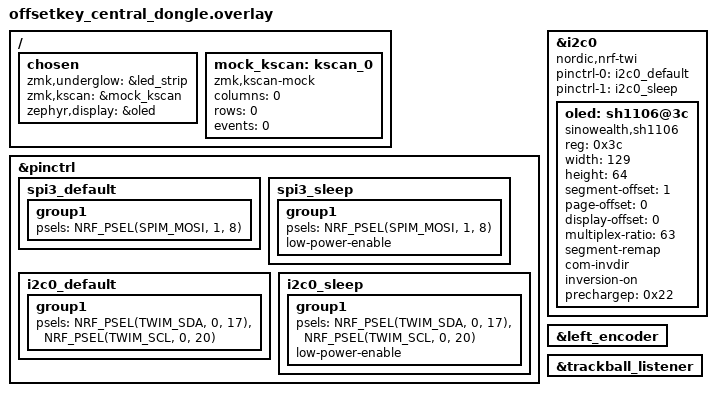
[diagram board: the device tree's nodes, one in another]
/*
 * Copyright (c) 2020 ZMK Contributors
 *
 * SPDX-License-Identifier: MIT
 */
#include <dt-bindings/led/led.h>
#include <input/processors.dtsi>
#include "offsetkey.dtsi"
#include "rgb.dtsi"
#include "split_input_common.dtsi"
#include "trackball.dtsi"
#define SYMBOLS 2

/ {
	chosen {
        zmk,underglow = &led_strip;
        zmk,kscan = &mock_kscan;
        zephyr,display = &oled;
    };
    mock_kscan: kscan_0 {
        compatible = "zmk,kscan-mock";
        columns = <0>;
        rows = <0>;
        events = <0>;
    };
};


&pinctrl {

    spi3_default: spi3_default {
        group1 {
            psels = <NRF_PSEL(SPIM_MOSI, 1, 8)>; // WS2812_VEXT_DATA
        };
    };

    spi3_sleep: spi3_sleep {
        group1 {
            psels = <NRF_PSEL(SPIM_MOSI, 1, 8)>;
            low-power-enable;
        };
    };

    i2c0_default: i2c0_default {
        group1 {
            psels = <NRF_PSEL(TWIM_SDA, 0, 17)>,
                <NRF_PSEL(TWIM_SCL, 0, 20)>;
        };
    };

    i2c0_sleep: i2c0_sleep {
        group1 {
            psels = <NRF_PSEL(TWIM_SDA, 0, 17)>,
                <NRF_PSEL(TWIM_SCL, 0, 20)>;
            low-power-enable;
        };
    };	
};

&i2c0 {
	status = "okay";
	compatible = "nordic,nrf-twi";
    pinctrl-0 = <&i2c0_default>;
    pinctrl-1 = <&i2c0_sleep>;
	oled: sh1106@3c {
        compatible = "sinowealth,sh1106";
        reg = <0x3c>;
        width = <129>;
        height = <64>;
        segment-offset = <1>;
        page-offset = <0>;
        display-offset = <0>;
        multiplex-ratio = <63>;
        segment-remap;
        com-invdir;
        inversion-on;
        prechargep = <0x22>;
	};
};
&left_encoder {
    status = "okay";
};

&trackball_listener {
    status = "okay";
};
